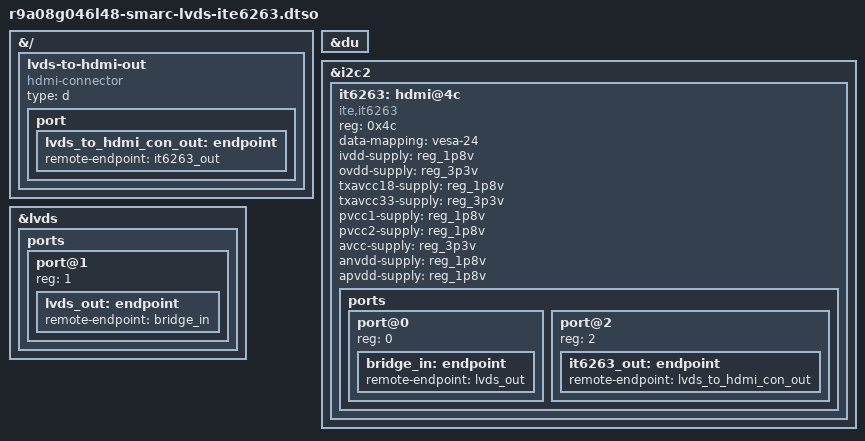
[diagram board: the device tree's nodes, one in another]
// SPDX-License-Identifier: (GPL-2.0-only OR BSD-2-Clause)
/*
 * Device Tree overlay for the RZ/G3L SMARC EVK with ITE6263
 * connected to LVDS and LCDC enabled.
 *
 * Copyright (C) 2026 Renesas Electronics Corp.
 */

/dts-v1/;
/plugin/;

#include <dt-bindings/gpio/gpio.h>
#include <dt-bindings/interrupt-controller/arm-gic.h>
#include <dt-bindings/pinctrl/renesas,r9a08g046-pinctrl.h>

&{/} {
	lvds-to-hdmi-out {
		compatible = "hdmi-connector";
		type = "d";

		port {
			lvds_to_hdmi_con_out: endpoint {
				remote-endpoint = <&it6263_out>;
			};
		};
	};
};

&du {
	status = "okay";
};

&i2c2 {
	#address-cells = <1>;
	#size-cells = <0>;

	it6263: hdmi@4c {
		compatible = "ite,it6263";
		reg = <0x4c>;
		data-mapping = "vesa-24";
		ivdd-supply = <&reg_1p8v>;
		ovdd-supply = <&reg_3p3v>;
		txavcc18-supply = <&reg_1p8v>;
		txavcc33-supply = <&reg_3p3v>;
		pvcc1-supply = <&reg_1p8v>;
		pvcc2-supply = <&reg_1p8v>;
		avcc-supply = <&reg_3p3v>;
		anvdd-supply = <&reg_1p8v>;
		apvdd-supply = <&reg_1p8v>;

		ports {
			#address-cells = <1>;
			#size-cells = <0>;

			port@0 {
				reg = <0>;
				bridge_in: endpoint {
					remote-endpoint = <&lvds_out>;
				};
			};

			port@2 {
				reg = <2>;
				it6263_out: endpoint {
					remote-endpoint = <&lvds_to_hdmi_con_out>;
				};
			};
		};
	};
};

&lvds {
	status = "okay";

	ports {
		#address-cells = <1>;
		#size-cells = <0>;

		port@1 {
			reg = <1>;
			lvds_out: endpoint {
				remote-endpoint = <&bridge_in>;
			};
		};
	};
};
